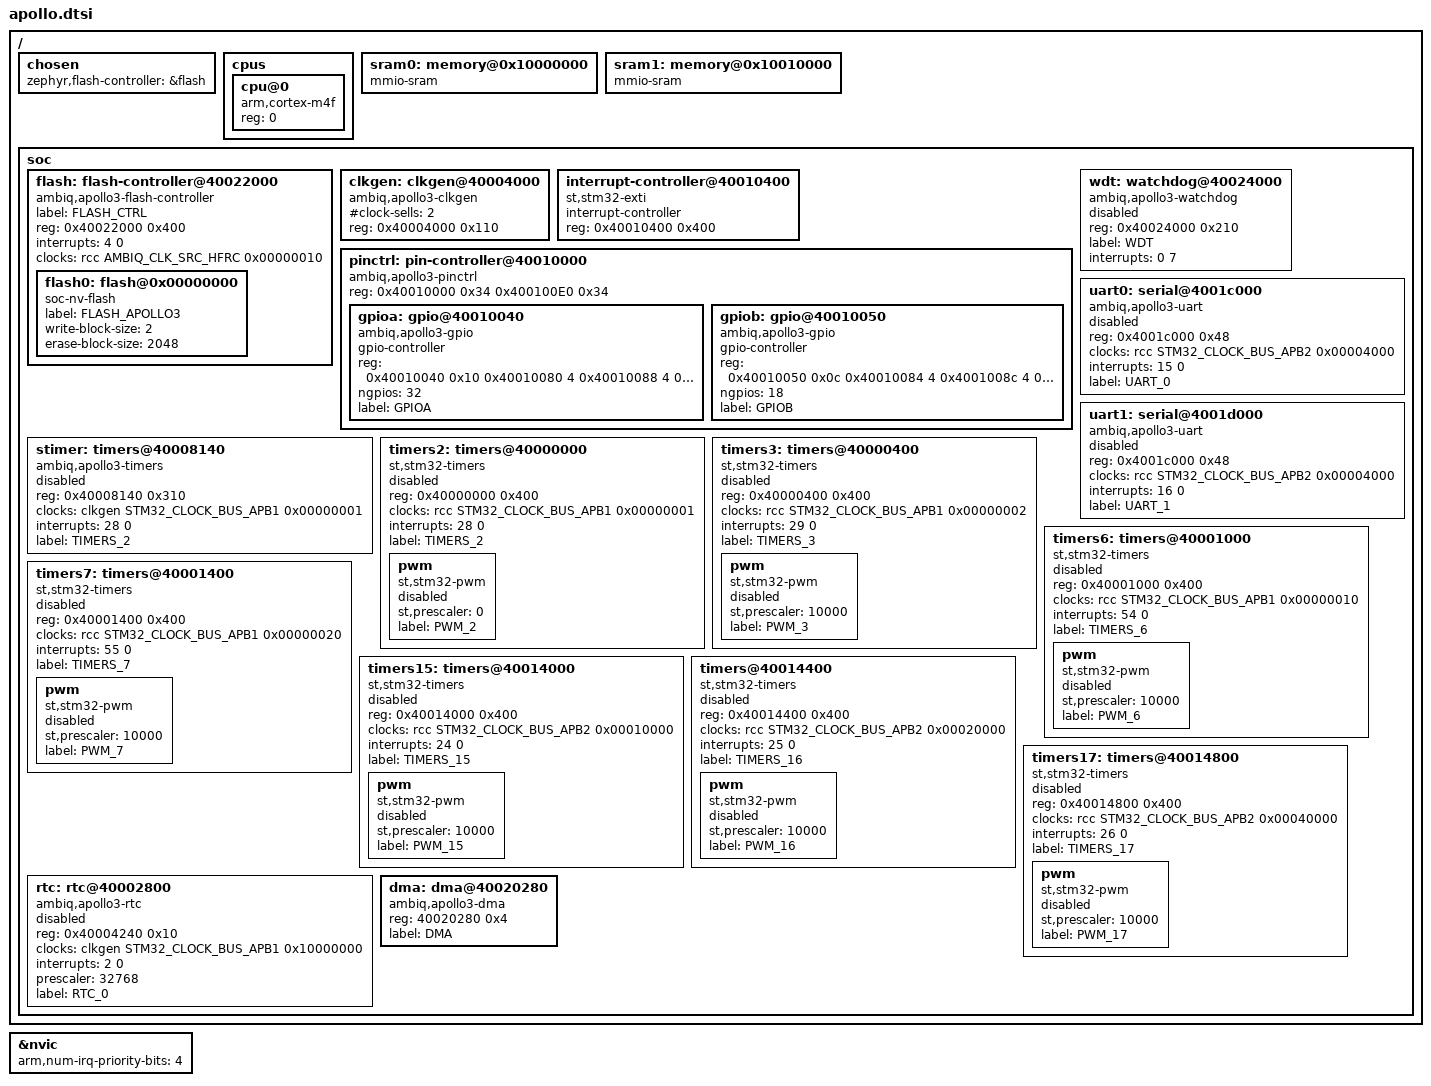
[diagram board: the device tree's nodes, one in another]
/*
 * Copyright (c) 2017 I-SENSE group of ICCS
 * Copyright (c) 2019 Centaur Analytics, Inc
 *
 * SPDX-License-Identifier: Apache-2.0
 */

#include <arm/armv7-m.dtsi>
#include <dt-bindings/clock/ambiq_clock.h>
#include <dt-bindings/i2c/i2c.h>
#include <dt-bindings/gpio/gpio.h>
#include <dt-bindings/pwm/pwm.h>

/ {
	chosen {
		zephyr,flash-controller = &flash;
	};

	cpus {
		#address-cells = <1>;
		#size-cells = <0>;

		cpu@0 {
			device_type = "cpu";
			compatible = "arm,cortex-m4f";
			reg = <0>;
		};
	};

	sram0: memory@0x10000000 {
		compatible = "mmio-sram";
	};

	sram1: memory@0x10010000 {
		compatible = "mmio-sram";
	};

	soc {
		flash: flash-controller@40022000 {
			compatible = "ambiq,apollo3-flash-controller";
			label = "FLASH_CTRL";
			reg = <0x40022000 0x400>;
			interrupts = <4 0>;
			clocks = <&rcc AMBIQ_CLK_SRC_HFRC 0x00000010>;

			#address-cells = <1>;
			#size-cells = <1>;

			flash0: flash@0x00000000 {
				compatible = "soc-nv-flash";
				label = "FLASH_APOLLO3";

				write-block-size = <2>;
				erase-block-size = <2048>;
			};
		};

		clkgen: clkgen@40004000 {
		compatible = "ambiq,apollo3-clkgen";
		#clock-sells = <2>;
		reg = <0x40004000 0x110>;
		};

		there is an interrupt enable bits in register 0x5000C220

		exti: interrupt-controller@40010400 {
			compatible = "st,stm32-exti";
			interrupt-controller;
			#interrupt-cells = <1>;
			reg = <0x40010400 0x400>;
		};

		pinctrl: pin-controller@40010000 {
			compatible = "ambiq,apollo3-pinctrl";
			#address-cells = <1>;
			#size-cells = <1>;
			reg = <0x40010000 0x34 0x400100E0 0x34>;

			gpioa: gpio@40010040 {
				compatible = "ambiq,apollo3-gpio";
				gpio-controller;
				reg = <0x40010040 0x10   /* CFG */
				       0x40010080 4      /* RD (input status) */
				       0x40010088 4      /* WT (output status) */
				       0x40010090 4      /* WTS (output enable) */
				       0x40010098 4      /* WTC (output disable) */
				       0x400100a0 4      /* EN (high impendance status) */
				       0x400100a8 4      /* ENS (high impendance enable) */
				       0x400100b4 4      /* ENC (high impendance disable) */
				       >;
				ngpios = <32>;   // pads 0-31
				label = "GPIOA";
				#gpio-cells = <2>;
			};

			gpiob: gpio@40010050 {
				compatible = "ambiq,apollo3-gpio";
				gpio-controller;
				reg = <0x40010050 0x0c   /* CFG */
				       0x40010084 4      /* RD (input status) */
				       0x4001008c 4      /* WT (output status) */
				       0x40010094 4      /* WTS (output enable) */
				       0x4001009c 4      /* WTC (output disable) */
				       0x400100a4 4      /* EN (high impendance status) */
				       0x400100ac 4      /* ENS (high impendance enable) */
				       0x400100b8 4      /* ENC (high impendance disable) */
				       >;
				ngpios = <18>;   // pads 32-49
				label = "GPIOB";
				#gpio-cells = <2>;
			};
		};

		wdt: watchdog@40024000 {
			compatible = "ambiq,apollo3-watchdog";
			reg = <0x40024000 0x210>;
			label = "WDT";
			interrupts = <0 7>;
			status = "disabled";
		};

		uart0: serial@4001c000 {
			compatible = "ambiq,apollo3-uart", "ambiq,apollo3-uart";
			reg = <0x4001c000 0x48>;
			clocks = <&rcc STM32_CLOCK_BUS_APB2 0x00004000>;
			interrupts = <15 0>;
			status = "disabled";
			label = "UART_0";
		};

		uart1: serial@4001d000 {
			compatible = "ambiq,apollo3-uart", "ambiq,apollo3-uart";
			reg = <0x4001c000 0x48>;
			clocks = <&rcc STM32_CLOCK_BUS_APB2 0x00004000>;
			interrupts = <16 0>;
			status = "disabled";
			label = "UART_1";
		};

		stimer: timers@40008140 {
			compatible = "ambiq,apollo3-timers";
			reg = <0x40008140 0x310>;
			clocks = <&clkgen STM32_CLOCK_BUS_APB1 0x00000001>;
			interrupts = <28 0>;
			interrupt-names = "global";
			status = "disabled";
			label = "TIMERS_2";
		};

		timers2: timers@40000000 {
			compatible = "st,stm32-timers";
			reg = <0x40000000 0x400>;
			clocks = <&rcc STM32_CLOCK_BUS_APB1 0x00000001>;
			interrupts = <28 0>;
			interrupt-names = "global";
			status = "disabled";
			label = "TIMERS_2";

			pwm {
				compatible = "st,stm32-pwm";
				status = "disabled";
				st,prescaler = <0>;
				label = "PWM_2";
				#pwm-cells = <3>;
			};
		};

		timers3: timers@40000400 {
			compatible = "st,stm32-timers";
			reg = <0x40000400 0x400>;
			clocks = <&rcc STM32_CLOCK_BUS_APB1 0x00000002>;
			interrupts = <29 0>;
			interrupt-names = "global";
			status = "disabled";
			label = "TIMERS_3";

			pwm {
				compatible = "st,stm32-pwm";
				status = "disabled";
				st,prescaler = <10000>;
				label = "PWM_3";
				#pwm-cells = <3>;
			};
		};

		timers6: timers@40001000 {
			compatible = "st,stm32-timers";
			reg = <0x40001000 0x400>;
			clocks = <&rcc STM32_CLOCK_BUS_APB1 0x00000010>;
			interrupts = <54 0>;
			interrupt-names = "global";
			status = "disabled";
			label = "TIMERS_6";

			pwm {
				compatible = "st,stm32-pwm";
				status = "disabled";
				st,prescaler = <10000>;
				label = "PWM_6";
				#pwm-cells = <3>;
			};
		};

		timers7: timers@40001400 {
			compatible = "st,stm32-timers";
			reg = <0x40001400 0x400>;
			clocks = <&rcc STM32_CLOCK_BUS_APB1 0x00000020>;
			interrupts = <55 0>;
			interrupt-names = "global";
			status = "disabled";
			label = "TIMERS_7";

			pwm {
				compatible = "st,stm32-pwm";
				status = "disabled";
				st,prescaler = <10000>;
				label = "PWM_7";
				#pwm-cells = <3>;
			};
		};

		timers15: timers@40014000 {
			compatible = "st,stm32-timers";
			reg = <0x40014000 0x400>;
			clocks = <&rcc STM32_CLOCK_BUS_APB2 0x00010000>;
			interrupts = <24 0>;
			interrupt-names = "global";
			status = "disabled";
			label = "TIMERS_15";

			pwm {
				compatible = "st,stm32-pwm";
				status = "disabled";
				st,prescaler = <10000>;
				label = "PWM_15";
				#pwm-cells = <3>;
			};
		};

		Stime Compare[0:7]      irq23-30
		Stime Capture/Overflow  irq22
		Counter/Timers          irq14

		timers16: timers@40014400 {
			compatible = "st,stm32-timers";
			reg = <0x40014400 0x400>;
			clocks = <&rcc STM32_CLOCK_BUS_APB2 0x00020000>;
			interrupts = <25 0>;
			interrupt-names = "global";
			status = "disabled";
			label = "TIMERS_16";

			pwm {
				compatible = "st,stm32-pwm";
				status = "disabled";
				st,prescaler = <10000>;
				label = "PWM_16";
				#pwm-cells = <3>;
			};
		};

		timers17: timers@40014800 {
			compatible = "st,stm32-timers";
			reg = <0x40014800 0x400>;
			clocks = <&rcc STM32_CLOCK_BUS_APB2 0x00040000>;
			interrupts = <26 0>;
			interrupt-names = "global";
			status = "disabled";
			label = "TIMERS_17";

			pwm {
				compatible = "st,stm32-pwm";
				status = "disabled";
				st,prescaler = <10000>;
				label = "PWM_17";
				#pwm-cells = <3>;
			};
		};

		rtc: rtc@40002800 {
			compatible = "ambiq,apollo3-rtc";
			reg = <0x40004240 0x10>;
			clocks = <&clkgen STM32_CLOCK_BUS_APB1 0x10000000>;
			interrupts = <2 0>;
			prescaler = <32768>;
			status = "disabled";
			label = "RTC_0";
		};

		dma: dma@40020280 {
			compatible = "ambiq,apollo3-dma";
			#dma-cells = <4>;
			reg = <40020280 0x4>;
			status = "okay";
			label = "DMA";
		};
	};
};

&nvic {
	arm,num-irq-priority-bits = <4>;
};
